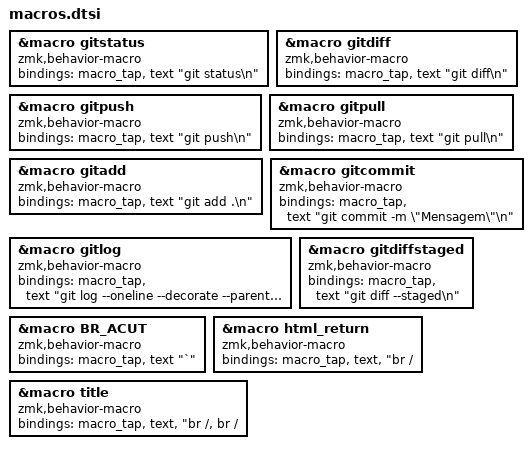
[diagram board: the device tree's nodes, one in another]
&macro gitstatus {
    compatible = "zmk,behavior-macro";
    bindings = <&macro_tap &text "git status\n">;
};

&macro gitdiff {
    compatible = "zmk,behavior-macro";
    bindings = <&macro_tap &text "git diff\n">;
};

&macro gitpush {
    compatible = "zmk,behavior-macro";
    bindings = <&macro_tap &text "git push\n">;
};

&macro gitpull {
    compatible = "zmk,behavior-macro";
    bindings = <&macro_tap &text "git pull\n">;
};

&macro gitadd {
    compatible = "zmk,behavior-macro";
    bindings = <&macro_tap &text "git add .\n">;
};

&macro gitcommit {
    compatible = "zmk,behavior-macro";
    bindings = <&macro_tap &text "git commit -m \"Mensagem\"\n">;
};

&macro gitlog {
    compatible = "zmk,behavior-macro";
    bindings = <&macro_tap &text "git log --oneline --decorate --parents\n">;
};

&macro gitdiffstaged {
    compatible = "zmk,behavior-macro";
    bindings = <&macro_tap &text "git diff --staged\n">;
};

&macro BR_ACUT {
    compatible = "zmk,behavior-macro";
    bindings = <&macro_tap &text "`">;
};

&macro html_return {
    compatible = "zmk,behavior-macro";
    bindings = <&macro_tap &text "<br />\n">;
};

&macro title {
    compatible = "zmk,behavior-macro";
    bindings = <&macro_tap &text "<br />\n\n<br />\n\n## \n----\n">;
};
